# ATtiny861A register map
Vendor: Atmel; File version: 1.0
CPU: other r0p0, little endian, no MPU, no FPU, 4 interrupt priority bits
Registers are 8-bit, read-write, reset 0x0 unless marked. A register's access mark holds for its fields unless they carry their own. Offsets are from the block's base; [hi:lo] are bit positions.

## TC1 — Timer/Counter, 16-bit
Base 0x00800020
0x00 TCCR1E — Timer/Counter1 Control Register E
  [5:0] OC1OE — Output Compare Override Enable Bits
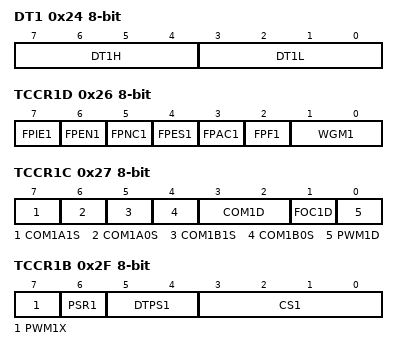
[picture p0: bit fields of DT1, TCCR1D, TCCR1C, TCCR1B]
0x24 DT1 — Timer/Counter 1 Dead Time Value
  [7:4] DT1H, [3:0] DT1L
0x25 TC1H — Timer/Counter 1 Register High
0x26 TCCR1D — Timer/Counter Control Register D
  [7] FPIE1 — Fault Protection Interrupt Enable
  [6] FPEN1 — Fault Protection Mode Enable
  [5] FPNC1 — Fault Protection Noise Canceler
  [4] FPES1 — Fault Protection Edge Select
  [3] FPAC1 — Fault Protection Analog Comparator Enable
  [2] FPF1 — Fault Protection Interrupt Flag
  [1:0] WGM1 — Waveform Generation Mode Bit
    0=FAST_PWM_NB_PWMX_MUST_BE_SET; 1=PHASE_AND_FREQUENCY_CORRECT_PWM; 2=PWM6_SINGLE_SLOPE; 3=PWM6_DUAL_SLOPE
0x27 TCCR1C — Timer/Counter Control Register C
  [7] COM1A1S — COM1A1 Shadow Bit
  [6] COM1A0S — COM1A0 Shadow Bit
  [5] COM1B1S — COM1B1 Shadow Bit
  [4] COM1B0S — COM1B0 Shadow Bit
  [3:2] COM1D — Comparator D output mode
  [1] FOC1D — Force Output Compare Match 1D
  [0] PWM1D — Pulse Width Modulator D Enable
0x2A OCR1D — Output compare register (read-only for debugger)
0x2B OCR1C — Output compare register
0x2C OCR1B — Output Compare Register
0x2D OCR1A — Output Compare Register
0x2E TCNT1 — Timer/Counter Register (read-only for debugger)
0x2F TCCR1B — Timer/Counter Control Register B
  [7] PWM1X — PWM Inversion Mode
  [6] PSR1 — Timer/Counter 1 Prescaler reset
  [5:4] DTPS1 — Dead Time Prescaler
    0=1X; 1=2X; 2=4X; 3=8X
  [3:0] CS1 — Clock Select Bits
    0=NO_CLOCK_SOURCE_STOPPED; 1=RUNNING_NO_PRESCALING; 2=RUNNING_CLK_2; 3=RUNNING_CLK_4; 4=RUNNING_CLK_8; 5=RUNNING_CLK_16; 6=RUNNING_CLK_32; 7=RUNNING_CLK_64; 8=RUNNING_CLK_128; 9=RUNNING_CLK_256; 10=RUNNING_CLK_512; 11=RUNNING_CLK_1024; 12=RUNNING_CLK_2048; 13=RUNNING_CLK_4096; 14=RUNNING_CLK_8192; 15=RUNNING_CLK_16384
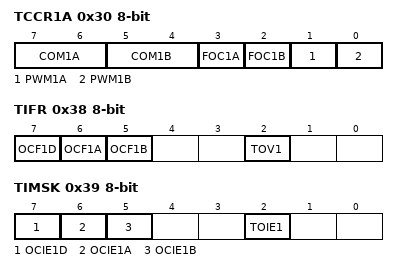
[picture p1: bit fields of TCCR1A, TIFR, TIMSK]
0x30 TCCR1A — Timer/Counter Control Register A
  [7:6] COM1A — Compare Output Mode, Bits
  [5:4] COM1B — Compare Output Mode, Bits
  [3] FOC1A — Force Output Compare Match 1A
  [2] FOC1B — Force Output Compare Match 1B
  [1] PWM1A — Pulse Width Modulator Enable
  [0] PWM1B — Pulse Width Modulator Enable
0x38 TIFR — Timer/Counter Interrupt Flag Register (read-only for debugger)
  [7] OCF1D — Timer/Counter1 Output Compare Flag 1D
  [6] OCF1A — Timer/Counter1 Output Compare Flag 1A
  [5] OCF1B — Timer/Counter1 Output Compare Flag 1B
  [2] TOV1 — Timer/Counter1 Overflow Flag
0x39 TIMSK — Timer/Counter Interrupt Mask Register
  [7] OCIE1D — OCIE1D: Timer/Counter1 Output Compare Interrupt Enable
  [6] OCIE1A — OCIE1A: Timer/Counter1 Output Compare Interrupt Enable
  [5] OCIE1B — OCIE1A: Timer/Counter1 Output Compare B Interrupt Enable
  [2] TOIE1 — Timer/Counter1 Overflow Interrupt Enable

## USI — Universal Serial Interface
Base 0x0080002D
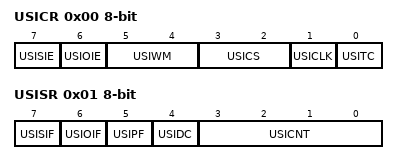
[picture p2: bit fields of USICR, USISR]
0x00 USICR — USI Control Register
  [7] USISIE — Start Condition Interrupt Enable
  [6] USIOIE — Counter Overflow Interrupt Enable
  [5:4] USIWM — USI Wire Mode Bits
    0=NORMAL_OPERATION; 1=THREE_WIRE_MODE; 2=TWO_WIRE_MODE; 3=TWO_WIRE_MODE_HELD_LOW
  [3:2] USICS — USI Clock Source Select Bits
  [1] USICLK — Clock Strobe
  [0] USITC — Toggle Clock Port Pin
0x01 USISR — USI Status Register (read-only for debugger)
  [7] USISIF — Start Condition Interrupt Flag
  [6] USIOIF — Counter Overflow Interrupt Flag
  [5] USIPF — Stop Condition Flag
  [4] USIDC — Data Output Collision
  [3:0] USICNT — USI Counter Value Bits
0x02 USIDR — USI Data Register
0x03 USIBR — USI Buffer Register (read-only for debugger)
0x04 USIPP — USI Pin Position

## WDT — Watchdog Timer
Base 0x00800041
0x00 WDTCR — Watchdog Timer Control Register (read-only for debugger)
  [7] WDIF — Watchdog Timeout Interrupt Flag
  [6] WDIE — Watchdog Timeout Interrupt Enable
  [4] WDCE — Watchdog Change Enable
  [3] WDE — Watch Dog Enable
  [5:0] WDP — Watchdog Timer Prescaler Bits
    0=OSCILLATOR_CYCLES_2K; 1=OSCILLATOR_CYCLES_4K; 2=OSCILLATOR_CYCLES_8K; 3=OSCILLATOR_CYCLES_16K; 4=OSCILLATOR_CYCLES_32K; 5=OSCILLATOR_CYCLES_64K; 6=OSCILLATOR_CYCLES_128K; 7=OSCILLATOR_CYCLES_256K
